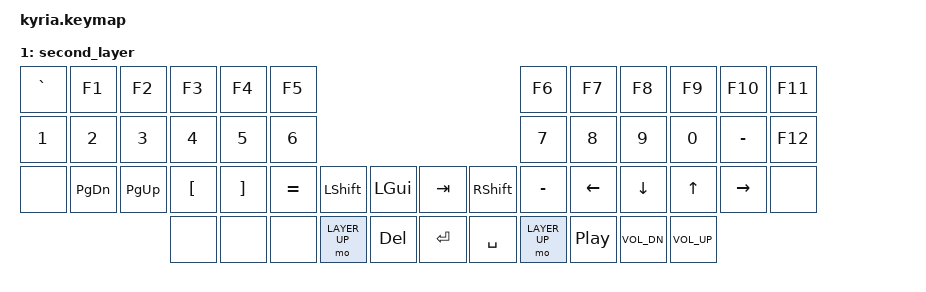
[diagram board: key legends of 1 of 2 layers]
/*
 * Copyright (c) 2020 The ZMK Contributors
 *
 * SPDX-License-Identifier: MIT
 */

#include <behaviors.dtsi>
#include <dt-bindings/zmk/keys.h>

#define DEFAULT  0
#define LAYER_UP 1

/ {
	keymap {
		compatible = "zmk,keymap";
		default_layer {
// ---------------------------------------------------------------------------------------------------------------------------------
// | TAB   |  Q  |  W  |  E   |  R   |  T   |                                          |  Y   |  U    |  I    |  O   |   P   |   \  |
// | LSHFT |  A  |  S  |  D   |  F   |  G   |                                          |  H   |  J    |  K    |  L   |   ;   |   '  |
// | LCTRL |  Z  |  X  |  C   |  V   |  B   | LGUI  | ESC  |           | RET   | L1    |  N   |  M    |  ,    |  .   |   /   | RCTRL|
//                     | none | none | LALT | SPACE | BSPC |           | RET   | TAB   | RALT | none  | none  |
		bindings = <
   &kp TAB   &kp Q &kp W &kp E &kp R &kp T                                                     &kp Y      &kp U   &kp I     &kp O     &kp P    &kp BSLH
   &kp ESC   &kp A &kp S &kp D &kp F &kp G                                                     &kp H      &kp J   &kp K     &kp L     &kp SEMI &kp SQT
   &kp LCTRL &kp Z &kp X &kp C &kp V &kp B    &kp LSHFT    &kp LGUI     &kp TAB   &kp RSHFT    &kp N      &kp M   &kp COMMA &kp DOT   &kp FSLH &kp RCTRL
	                 &none &none &kp LALT &mo LAYER_UP &kp BSPC     &kp RET   &kp SPACE &kp RALT   &none   &none 
			>;
			sensor-bindings = <&inc_dec_kp C_VOL_UP C_VOL_DN &inc_dec_kp PG_UP PG_DN>;
		};


		second_layer {
// ---------------------------------------------------------------------------------------------------------------------------------
// |   `   |  F1  |  F2  |  F3  |  F4  |  F5  |                                       |  F6   |  F7   |  F8    |   F9   |  F10  | F11  |
// | LSHFT |   1  |   2  |   3  |   4  |   5  |                                       |   6   |   7   |   8    |    9   |    0  | F12  |
// | none  | none | none |   [  |   ]  |   +  | LGUI  | ESC   |         | RET  | L1   |   -   | LEFT  |  DOWN  |   UP   | RIGHT | none |
//                       | none | none | none | LSHFT | DELETE|         | RET  | TAB  | playp | V-    |  V+    |
		bindings = <
   &kp GRAVE &kp F1    &kp F2    &kp F3   &kp F4   &kp F5                                                   &kp F6    &kp F7       &kp F8       &kp F9   &kp F10   &kp F11  
   &kp N1    &kp N2    &kp N3    &kp N4   &kp N5   &kp N6                                                   &kp N7    &kp N8       &kp N9       &kp N0   &kp MINUS &kp F12
   &none     &kp PG_DN &kp PG_UP &kp LBKT &kp RBKT &kp EQUAL &kp LSHFT    &kp LGUI       &kp TAB &kp RSHFT  &kp MINUS &kp LEFT     &kp DOWN     &kp UP   &kp RIGHT &none
                                 &none    &none    &none     &mo LAYER_UP &kp DEL        &kp RET &kp SPACE  &mo LAYER_UP &kp C_PP  &kp K_VOL_DN &kp K_VOL_UP 
			>;
			sensor-bindings = < &inc_dec_kp C_VOL_UP C_VOL_DN &inc_dec_kp C_BRI_DN C_BRI_UP >;
		};
	};
};
